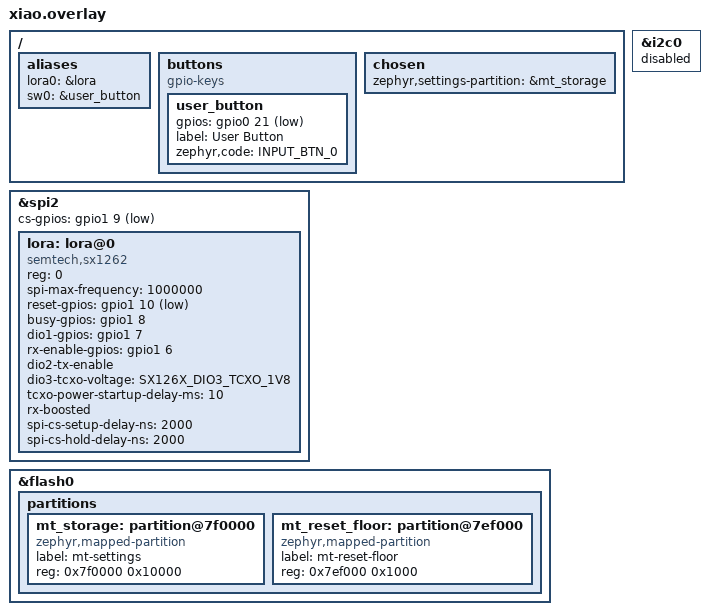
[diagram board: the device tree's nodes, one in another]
/*
 * SPDX-License-Identifier: MIT
 * Seeed XIAO ESP32-S3 + WIO-SX1262 LoRa
 *
 * Pin mapping (from Arduino MeshCore variants/xiao_s3_wio):
 * - GPIO41 (gpio1 pin 9)  = NSS     - GPIO7  (gpio0 pin 7)  = SPI SCK
 * - GPIO39 (gpio1 pin 7)  = DIO1    - GPIO8  (gpio0 pin 8)  = SPI MISO
 * - GPIO40 (gpio1 pin 8)  = BUSY    - GPIO9  (gpio0 pin 9)  = SPI MOSI
 * - GPIO42 (gpio1 pin 10) = RESET
 * - GPIO38 (gpio1 pin 6)  = RXEN
 * - GPIO21 (gpio0 pin 21) = User button
 * - GPIO48 (gpio1 pin 16) = Status LED
 *
 * SPI2 SCK/MISO/MOSI pinctrl already set in Zephyr board DTS.
 * Console: USB Serial/JTAG (usb_serial) — already set in board DTS.
 */

#include <zephyr/dt-bindings/lora/sx126x.h>
#include <zephyr/dt-bindings/input/input-event-codes.h>
#include <zephyr/dt-bindings/gpio/espressif-esp32-gpio.h>

/ {
	aliases {
		lora0 = &lora;
		sw0 = &user_button;
		/delete-property/ led0;
	};

	buttons: buttons {
		compatible = "gpio-keys";
		user_button: user_button {
			/* GPIO21 is also the XIAO's onboard LED line, which does not
			 * pull the pad to a defined level: without the pull-up the
			 * input floats, reads "pressed", and (with CONFIG_PM) wakes
			 * the SoC as soon as it sleeps. */
			gpios = <&gpio0 21 (GPIO_ACTIVE_LOW | GPIO_PULL_UP)>;
			label = "User Button";
			zephyr,code = <INPUT_BTN_0>;
		};
	};
};

/* GPIO21 is the user button on the Wio-SX1262 kit (as upstream MeshCore:
 * PIN_USER_BTN=21) and also the XIAO's onboard LED line.  The Zephyr board
 * declares it led0, and ZephCore's heartbeat drives led0 — which pulled the
 * button low, read as a press, and (with CONFIG_PM) woke the SoC and reopened
 * the console window after every sleep.  The button owns the pin. */
/delete-node/ &led0;

/* SX1262 on SPI2 (SCK=GPIO7, MISO=GPIO8, MOSI=GPIO9 — in board pinctrl) */
/* ESP32_GPIO_SLEEP_HOLD_EN on NSS, RESET and RXEN: light sleep isolates every
 * pad that is not held (boards/common/pm_esp32.overlay), and the radio keeps
 * receiving through the sleep.  RXEN is the MCU-driven half of the RF switch:
 * floating, the receive path is undefined.  Inert when CONFIG_PM=n. */
&spi2 {
	cs-gpios = <&gpio1 9 (GPIO_ACTIVE_LOW | ESP32_GPIO_SLEEP_HOLD_EN)>;  /* GPIO41 NSS */

	lora: lora@0 {
		compatible = "semtech,sx1262";
		reg = <0>;
		spi-max-frequency = <1000000>;

		/* LoRa control pins */
		reset-gpios = <&gpio1 10 (GPIO_ACTIVE_LOW | ESP32_GPIO_SLEEP_HOLD_EN)>;  /* GPIO42 */
		busy-gpios  = <&gpio1 8 GPIO_ACTIVE_HIGH>;                    /* GPIO40 */
		dio1-gpios  = <&gpio1 7 (GPIO_PULL_DOWN | GPIO_ACTIVE_HIGH)>; /* GPIO39 */

		/* RF switch: RXEN for RX, DIO2 drives TX enable */
		rx-enable-gpios = <&gpio1 6 (GPIO_ACTIVE_HIGH | ESP32_GPIO_SLEEP_HOLD_EN)>;  /* GPIO38 RXEN */
		dio2-tx-enable;

		/* TCXO 1.8V via DIO3 */
		dio3-tcxo-voltage = <SX126X_DIO3_TCXO_1V8>;
		tcxo-power-startup-delay-ms = <10>;

		/* RX boosted mode for better sensitivity */
		rx-boosted;
	};
};


&i2c0 { status = "disabled"; };
&spi2 { status = "okay"; };
&lora { spi-cs-setup-delay-ns = <2000>; spi-cs-hold-delay-ns = <2000>; };
/ { chosen { zephyr,settings-partition = &mt_storage; }; };
&flash0 { partitions { mt_storage: partition@7f0000 { compatible = "zephyr,mapped-partition"; label = "mt-settings"; reg = <0x7f0000 0x10000>; }; }; };

/* The 8-MiB XIAO's boot/OTA/storage partitions end below 0x400000.
 * This standalone erase page is outside both the firmware and mt-settings. */
&flash0 { partitions {
    mt_reset_floor: partition@7ef000 { compatible = "zephyr,mapped-partition"; label = "mt-reset-floor"; reg = <0x7ef000 0x1000>; };
}; };
